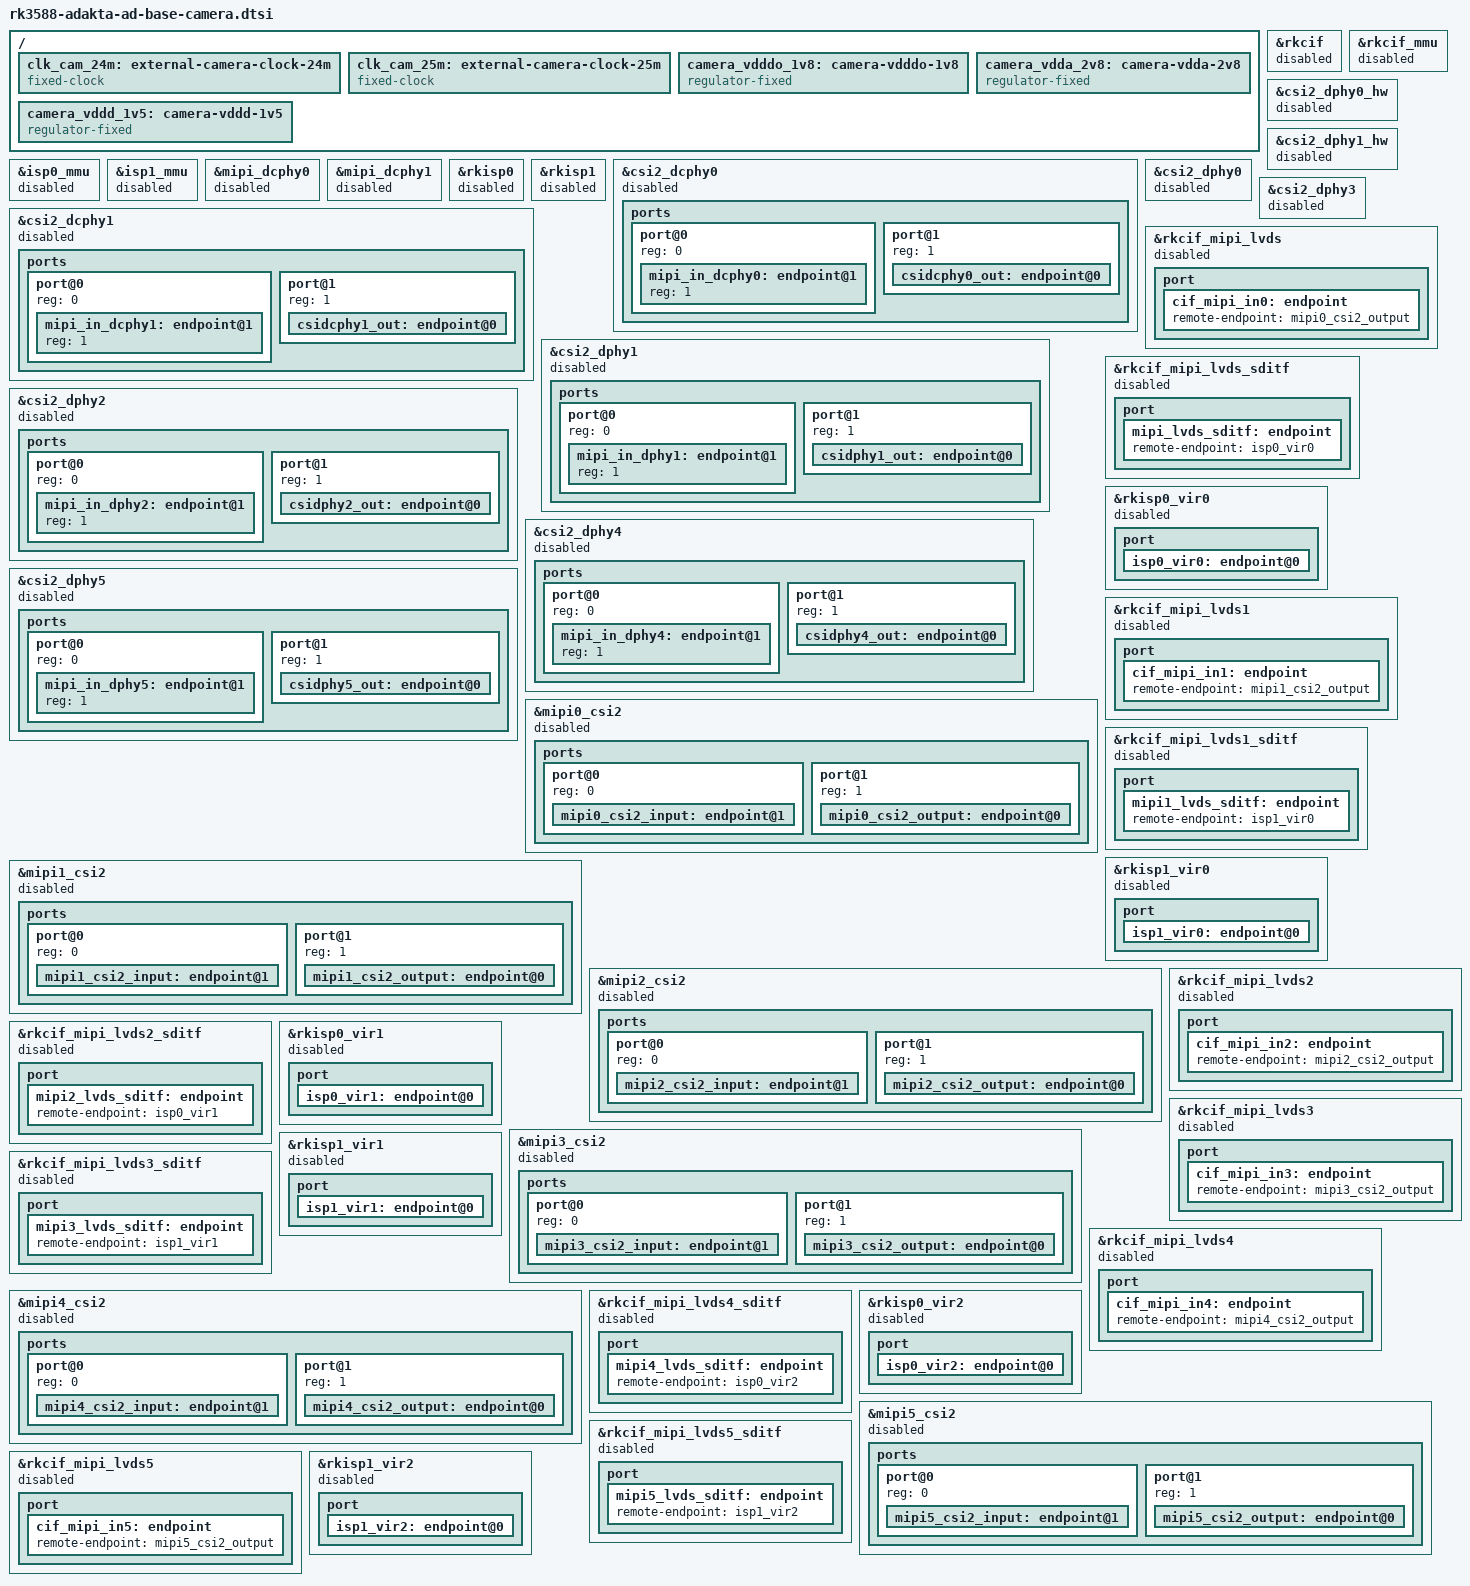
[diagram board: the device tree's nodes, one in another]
// SPDX-License-Identifier: (GPL-2.0+ OR MIT)
/*
 * Copyright (c) 2024 Adakta, Ltd.
 *

 * rkisp0 --> rkisp0_vir0/rkisp0_vir1/rkisp0_vir2/rkisp0_vir3
 * rkisp1 --> rkisp1_vir0/rkisp1_vir1/rkisp1_vir2/rkisp1_vir3

 * rkcif_mipi_lvds --> rkcif_mipi_lvds[0-4]_sditf

 * mipicamera0 --> csi2_dcphy0 --> mipi0_csi2 -->rkcif_mipi_lvds  --> rkcif_mipi_lvds_sditf  --> rkisp0_vir0
 * mipicamera1 --> csi2_dcphy1 --> mipi1_csi2 -->rkcif_mipi_lvds1 --> rkcif_mipi_lvds1_sditf --> rkisp0_vir1

 * csi2_dphy0 or (csi2_dphy1、csi2_dphy2)	dphy0
 * csi2_dphy3 or (csi2_dphy4、csi2_dphy5)	dphy1

 * mipicamera2 --> csi2_dphy1 -->  mipi2_csi2 -->rkcif_mipi_lvds2 -->rkcif_mipi_lvds2_sditf  --> rkisp0_vir2
 * mipicamera3 --> csi2_dphy2 -->  mipi3_csi2 -->rkcif_mipi_lvds3 -->rkcif_mipi_lvds3_sditf  --> rkisp1_vir0
 * mipicamera4 --> csi2_dphy4 -->  mipi4_csi2 -->rkcif_mipi_lvds4 -->rkcif_mipi_lvds4_sditf  --> rkisp1_vir1
 * mipicamera5 --> csi2_dphy5 -->  mipi5_csi2 -->rkcif_mipi_lvds5 -->rkcif_mipi_lvds5_sditf  --> rkisp1_vir2

 * mipicamera6 --> rkcif_dvp ---> rkcif_dvp_sditf
 */

/ {
	clk_cam_24m: external-camera-clock-24m {
		status = "okay";
		compatible = "fixed-clock";
		clock-frequency = <24000000>;
		clock-output-names = "clk_cam_24m";
		#clock-cells = <0>;
	};

	clk_cam_25m: external-camera-clock-25m {
		status = "okay";
		compatible = "fixed-clock";
		clock-frequency = <25000000>;
		clock-output-names = "clk_cam_25m";
		#clock-cells = <0>;
	};

	camera_vdddo_1v8: camera-vdddo-1v8 {
		compatible = "regulator-fixed";
		regulator-name = "camera_vdddo_1v8";
		regulator-min-microvolt = <1800000>;
		regulator-max-microvolt = <1800000>;
		regulator-always-on;
	};

	camera_vdda_2v8: camera-vdda-2v8 {
		compatible = "regulator-fixed";
		regulator-name = "camera_vdda_2v8";
		regulator-min-microvolt = <2800000>;
		regulator-max-microvolt = <2800000>;
		regulator-always-on;
	};

	camera_vddd_1v5: camera-vddd-1v5 {
		compatible = "regulator-fixed";
		regulator-name = "camera_vddd_1v5";
		regulator-min-microvolt = <1500000>;
		regulator-max-microvolt = <1500000>;
		regulator-always-on;
	};
};

/* must be enabled for any csi2 */
&rkcif {
	status = "disabled";
};

/* must be enabled for any csi2 */
&rkcif_mmu {
	status = "disabled";
};

/* must be enabled for "csi2_dphy0", "csi2_dphy1", "csi2_dphy2" */
&csi2_dphy0_hw {
	status = "disabled";
};

/* must be enabled for "csi2_dphy3", "csi2_dphy4", "csi2_dphy5" */
&csi2_dphy1_hw {
	status = "disabled";
};

/* must be disabled if camera has own ISP */
&isp0_mmu {
	status = "disabled";
};

/* must be disabled if camera has own ISP */
&isp1_mmu {
	status = "disabled";
};

/* must be enabled for "csi2_dcphy0" */
&mipi_dcphy0 {
	status = "disabled";
};

/* must be enabled for "csi2_dcphy1" */
&mipi_dcphy1 {
	status = "disabled";
};

/* must be disabled if camera has own ISP */
&rkisp0 {
	status = "disabled";
};

/* must be disabled if camera has own ISP */
&rkisp1 {
	status = "disabled";
};

/* MIPI_DPHY0_RX_D0/D1/D2/D3/CLK */
&csi2_dcphy0 {
	status = "disabled";
};

/* MIPI_DPHY1_RX_D0/D1/D2/D3/CLK */
&csi2_dcphy1 {
	status = "disabled";
};

/* MIPI_CSI0_RX_D0/D1/D2/D3/CLK0 */
&csi2_dphy0 {
	status = "disabled";
};

/* MIPI_CSI0_RX_D0/D1/CLK0 */
&csi2_dphy1 {
	status = "disabled";
};

/* MIPI_CSI0_RX_D2/D3/CLK1 */
&csi2_dphy2 {
	status = "disabled";
};

/* MIPI_CSI1_RX_D0/D1/D2/D3/CLK0 */
&csi2_dphy3 {
	status = "disabled";
};

/* MIPI_CSI1_RX_D0/D1/CLK0 */
&csi2_dphy4 {
	status = "disabled";
};

/* MIPI_CSI1_RX_D2/D3/CLK1 */
&csi2_dphy5 {
	status = "disabled";
};

//*********************************************
//*** CAM4 - MIPI_DPHY0_RX_D0/D1/D2/D3/CLK ****
//*********************************************

&csi2_dcphy0 {
	status = "disabled";

	ports {
		#address-cells = <1>;
		#size-cells = <0>;
		port@0 {
			reg = <0>;
			#address-cells = <1>;
			#size-cells = <0>;

			mipi_in_dcphy0: endpoint@1 {
				reg = <1>;
			};
		};
		port@1 {
			reg = <1>;
			#address-cells = <1>;
			#size-cells = <0>;

			csidcphy0_out: endpoint@0 {
				reg = <0>;
				remote-endpoint = <&mipi0_csi2_input>;
			};
		};
	};
};

&mipi0_csi2 {
	status = "disabled";

	ports {
		#address-cells = <1>;
		#size-cells = <0>;

		port@0 {
			reg = <0>;
			#address-cells = <1>;
			#size-cells = <0>;

			mipi0_csi2_input: endpoint@1 {
				reg = <1>;
				remote-endpoint = <&csidcphy0_out>;
			};
		};

		port@1 {
			reg = <1>;
			#address-cells = <1>;
			#size-cells = <0>;

			mipi0_csi2_output: endpoint@0 {
				reg = <0>;
				remote-endpoint = <&cif_mipi_in0>;
			};
		};
	};
};

&rkcif_mipi_lvds {
	status = "disabled";

	port {
		cif_mipi_in0: endpoint {
			remote-endpoint = <&mipi0_csi2_output>;
		};
	};
};

/* must be disabled if camera has own ISP */
&rkcif_mipi_lvds_sditf {
	status = "disabled";

	port {
		mipi_lvds_sditf: endpoint {
			remote-endpoint = <&isp0_vir0>;
		};
	};
};

/* must be disabled if camera has own ISP */
&rkisp0_vir0 {
	status = "disabled";

	port {
		#address-cells = <1>;
		#size-cells = <0>;

		isp0_vir0: endpoint@0 {
			reg = <0>;
			remote-endpoint = <&mipi_lvds_sditf>;
		};
	};
};

//*********************************************
//*** CAM5 - MIPI_DPHY1_RX_D0/D1/D2/D3/CLK ****
//*********************************************

&csi2_dcphy1 {
	status = "disabled";

	ports {
		#address-cells = <1>;
		#size-cells = <0>;
		port@0 {
			reg = <0>;
			#address-cells = <1>;
			#size-cells = <0>;

			mipi_in_dcphy1: endpoint@1 {
				reg = <1>;
			};
		};
		port@1 {
			reg = <1>;
			#address-cells = <1>;
			#size-cells = <0>;

			csidcphy1_out: endpoint@0 {
				reg = <0>;
				remote-endpoint = <&mipi1_csi2_input>;
			};
		};
	};
};

&mipi1_csi2 {
	status = "disabled";

	ports {
		#address-cells = <1>;
		#size-cells = <0>;

		port@0 {
			reg = <0>;
			#address-cells = <1>;
			#size-cells = <0>;

			mipi1_csi2_input: endpoint@1 {
				reg = <1>;
				remote-endpoint = <&csidcphy1_out>;
			};
		};

		port@1 {
			reg = <1>;
			#address-cells = <1>;
			#size-cells = <0>;

			mipi1_csi2_output: endpoint@0 {
				reg = <0>;
				remote-endpoint = <&cif_mipi_in1>;
			};
		};
	};
};

&rkcif_mipi_lvds1 {
	status = "disabled";

	port {
		cif_mipi_in1: endpoint {
			remote-endpoint = <&mipi1_csi2_output>;
		};
	};
};

/* must be disabled if camera has own ISP */
&rkcif_mipi_lvds1_sditf {
	status = "disabled";

	port {
		mipi1_lvds_sditf: endpoint {
			remote-endpoint = <&isp1_vir0>;
		};
	};
};

/* must be disabled if camera has own ISP */
&rkisp1_vir0 {
	status = "disabled";

	port {
		#address-cells = <1>;
		#size-cells = <0>;

		isp1_vir0: endpoint@0 {
			reg = <0>;
			remote-endpoint = <&mipi1_lvds_sditf>;
		};
	};
};

//***************************************
//*** CAM2 - MIPI_CSI0_RX_D0/D1/CLK0 ****
//***************************************

&csi2_dphy1 {
	status = "disabled";

	ports {
		#address-cells = <1>;
		#size-cells = <0>;
		port@0 {
			reg = <0>;
			#address-cells = <1>;
			#size-cells = <0>;

			mipi_in_dphy1: endpoint@1 {
				reg = <1>;
			};
		};
		port@1 {
			reg = <1>;
			#address-cells = <1>;
			#size-cells = <0>;

			csidphy1_out: endpoint@0 {
				reg = <0>;
				remote-endpoint = <&mipi2_csi2_input>;
			};
		};
	};
};

&mipi2_csi2 {
	status = "disabled";

	ports {
		#address-cells = <1>;
		#size-cells = <0>;

		port@0 {
			reg = <0>;
			#address-cells = <1>;
			#size-cells = <0>;

			mipi2_csi2_input: endpoint@1 {
				reg = <1>;
				remote-endpoint = <&csidphy1_out>;
			};
		};

		port@1 {
			reg = <1>;
			#address-cells = <1>;
			#size-cells = <0>;

			mipi2_csi2_output: endpoint@0 {
				reg = <0>;
				remote-endpoint = <&cif_mipi_in2>;
			};
		};
	};
};

&rkcif_mipi_lvds2 {
	status = "disabled";

	port {
		cif_mipi_in2: endpoint {
			remote-endpoint = <&mipi2_csi2_output>;
		};
	};
};

/* must be disabled if camera has own ISP */
&rkcif_mipi_lvds2_sditf {
	status = "disabled";

	port {
		mipi2_lvds_sditf: endpoint {
			remote-endpoint = <&isp0_vir1>;
		};
	};
};

/* must be disabled if camera has own ISP */
&rkisp0_vir1 {
	status = "disabled";

	port {
		#address-cells = <1>;
		#size-cells = <0>;

		isp0_vir1: endpoint@0 {
			reg = <0>;
			remote-endpoint = <&mipi2_lvds_sditf>;
		};
	};
};

//***************************************
//*** CAM3 - MIPI_CSI0_RX_D2/D3/CLK1 ****
//***************************************

&csi2_dphy2 {
	status = "disabled";

	ports {
		#address-cells = <1>;
		#size-cells = <0>;
		port@0 {
			reg = <0>;
			#address-cells = <1>;
			#size-cells = <0>;

			mipi_in_dphy2: endpoint@1 {
				reg = <1>;
			};
		};
		port@1 {
			reg = <1>;
			#address-cells = <1>;
			#size-cells = <0>;

			csidphy2_out: endpoint@0 {
				reg = <0>;
				remote-endpoint = <&mipi3_csi2_input>;
			};
		};
	};
};

&mipi3_csi2 {
	status = "disabled";

	ports {
		#address-cells = <1>;
		#size-cells = <0>;

		port@0 {
			reg = <0>;
			#address-cells = <1>;
			#size-cells = <0>;

			mipi3_csi2_input: endpoint@1 {
				reg = <1>;
				remote-endpoint = <&csidphy2_out>;
			};
		};

		port@1 {
			reg = <1>;
			#address-cells = <1>;
			#size-cells = <0>;

			mipi3_csi2_output: endpoint@0 {
				reg = <0>;
				remote-endpoint = <&cif_mipi_in3>;
			};
		};
	};
};

&rkcif_mipi_lvds3 {
	status = "disabled";

	port {
		cif_mipi_in3: endpoint {
			remote-endpoint = <&mipi3_csi2_output>;
		};
	};
};

/* must be disabled if camera has own ISP */
&rkcif_mipi_lvds3_sditf {
	status = "disabled";

	port {
		mipi3_lvds_sditf: endpoint {
			remote-endpoint = <&isp1_vir1>;
		};
	};
};

/* must be disabled if camera has own ISP */
&rkisp1_vir1 {
	status = "disabled";

	port {
		#address-cells = <1>;
		#size-cells = <0>;

		isp1_vir1: endpoint@0 {
			reg = <0>;
			remote-endpoint = <&mipi3_lvds_sditf>;
		};
	};
};

//***************************************
//*** CAM0 - MIPI_CSI1_RX_D0/D1/CLK0 ****
//***************************************

&csi2_dphy4 {
	status = "disabled";

	ports {
		#address-cells = <1>;
		#size-cells = <0>;
		port@0 {
			reg = <0>;
			#address-cells = <1>;
			#size-cells = <0>;

			mipi_in_dphy4: endpoint@1 {
				reg = <1>;
			};
		};
		port@1 {
			reg = <1>;
			#address-cells = <1>;
			#size-cells = <0>;

			csidphy4_out: endpoint@0 {
				reg = <0>;
				remote-endpoint = <&mipi4_csi2_input>;
			};
		};
	};
};

&mipi4_csi2 {
	status = "disabled";

	ports {
		#address-cells = <1>;
		#size-cells = <0>;

		port@0 {
			reg = <0>;
			#address-cells = <1>;
			#size-cells = <0>;

			mipi4_csi2_input: endpoint@1 {
				reg = <1>;
				remote-endpoint = <&csidphy4_out>;
			};
		};

		port@1 {
			reg = <1>;
			#address-cells = <1>;
			#size-cells = <0>;

			mipi4_csi2_output: endpoint@0 {
				reg = <0>;
				remote-endpoint = <&cif_mipi_in4>;
			};
		};
	};
};

&rkcif_mipi_lvds4 {
	status = "disabled";

	port {
		cif_mipi_in4: endpoint {
			remote-endpoint = <&mipi4_csi2_output>;
		};
	};
};

/* must be disabled if camera has own ISP */
&rkcif_mipi_lvds4_sditf {
	status = "disabled";

	port {
		mipi4_lvds_sditf: endpoint {
			remote-endpoint = <&isp0_vir2>;
		};
	};
};

/* must be disabled if camera has own ISP */
&rkisp0_vir2 {
	status = "disabled";

	port {
		#address-cells = <1>;
		#size-cells = <0>;

		isp0_vir2: endpoint@0 {
			reg = <0>;
			remote-endpoint = <&mipi4_lvds_sditf>;
		};
	};
};

//***************************************
//*** CAM1 - MIPI_CSI1_RX_D2/D3/CLK1 ****
//***************************************

&csi2_dphy5 {
	status = "disabled";

	ports {
		#address-cells = <1>;
		#size-cells = <0>;
		port@0 {
			reg = <0>;
			#address-cells = <1>;
			#size-cells = <0>;

			mipi_in_dphy5: endpoint@1 {
				reg = <1>;
			};
		};
		port@1 {
			reg = <1>;
			#address-cells = <1>;
			#size-cells = <0>;

			csidphy5_out: endpoint@0 {
				reg = <0>;
				remote-endpoint = <&mipi5_csi2_input>;
			};
		};
	};
};

&mipi5_csi2 {
	status = "disabled";

	ports {
		#address-cells = <1>;
		#size-cells = <0>;

		port@0 {
			reg = <0>;
			#address-cells = <1>;
			#size-cells = <0>;

			mipi5_csi2_input: endpoint@1 {
				reg = <1>;
				remote-endpoint = <&csidphy5_out>;
			};
		};

		port@1 {
			reg = <1>;
			#address-cells = <1>;
			#size-cells = <0>;

			mipi5_csi2_output: endpoint@0 {
				reg = <0>;
				remote-endpoint = <&cif_mipi_in5>;
			};
		};
	};
};

&rkcif_mipi_lvds5 {
	status = "disabled";

	port {
		cif_mipi_in5: endpoint {
			remote-endpoint = <&mipi5_csi2_output>;
		};
	};
};

/* must be disabled if camera has own ISP */
&rkcif_mipi_lvds5_sditf {
	status = "disabled";

	port {
		mipi5_lvds_sditf: endpoint {
			remote-endpoint = <&isp1_vir2>;
		};
	};
};

/* must be disabled if camera has own ISP */
&rkisp1_vir2 {
	status = "disabled";

	port {
		#address-cells = <1>;
		#size-cells = <0>;

		isp1_vir2: endpoint@0 {
			reg = <0>;
			remote-endpoint = <&mipi5_lvds_sditf>;
		};
	};
};
